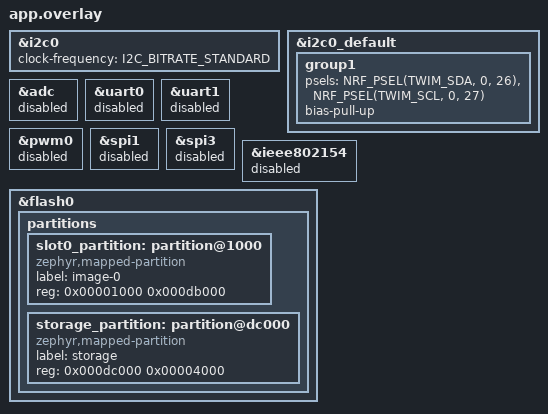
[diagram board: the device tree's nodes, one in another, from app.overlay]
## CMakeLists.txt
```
cmake_minimum_required(VERSION 3.20.0)
find_package(Zephyr REQUIRED HINTS $ENV{ZEPHYR_BASE})
project(nu40_imu_bringup)
target_include_directories(app PRIVATE include)
target_sources(app PRIVATE src/main.c src/imu_device.c src/imu_calibration.c src/imu_storage.c)
```

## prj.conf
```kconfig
CONFIG_GPIO=y
CONFIG_I2C=y
CONFIG_PINCTRL=y
CONFIG_CONSOLE=y
CONFIG_PRINTK=y
CONFIG_SHELL=y
CONFIG_SHELL_BACKEND_SERIAL=y
CONFIG_SHELL_VT100_COLORS=n
CONFIG_SHELL_STACK_SIZE=4096
CONFIG_UART_LINE_CTRL=y
CONFIG_LOG=y
CONFIG_LOG_MODE_DEFERRED=y
CONFIG_LOG_PROCESS_TRIGGER_THRESHOLD=1
CONFIG_LOG_PROCESS_THREAD_SLEEP_MS=20
CONFIG_LOG_DEFAULT_LEVEL=3
CONFIG_LOG_BACKEND_UART=n
CONFIG_LOG_BACKEND_SHOW_COLOR=n
CONFIG_LOG_BUFFER_SIZE=8192
CONFIG_CBPRINTF_FP_SUPPORT=y
CONFIG_MAIN_STACK_SIZE=4096
CONFIG_SYSTEM_WORKQUEUE_STACK_SIZE=2048
CONFIG_ASSERT=y
CONFIG_FLASH=y
CONFIG_FLASH_PAGE_LAYOUT=y
CONFIG_FLASH_MAP=y
CONFIG_NVS=y
CONFIG_NVS_DATA_CRC=y
CONFIG_BUILD_OUTPUT_UF2=y
CONFIG_USE_DT_CODE_PARTITION=y
```

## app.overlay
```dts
/* BARAM-NU40 UF2 bootloader, no SoftDevice: direct application starts at 0x1000.
 * Verified from this board's INFO_UF2.TXT. Not for the older NRF52BOOT/S140 board.
 */
&i2c0 {
	status = "okay";
	clock-frequency = <I2C_BITRATE_STANDARD>;
};

&i2c0_default {
	group1 {
		psels = <NRF_PSEL(TWIM_SDA, 0, 26)>, <NRF_PSEL(TWIM_SCL, 0, 27)>;
		bias-pull-up;
	};
};

&adc { status = "disabled"; };
&uart0 { status = "disabled"; };
&uart1 { status = "disabled"; };
&pwm0 { status = "disabled"; };
&spi1 { status = "disabled"; };
&spi3 { status = "disabled"; };
&ieee802154 { status = "disabled"; };

&flash0 {
	partitions {
		/delete-node/ partition@1000;
		/delete-node/ partition@10000;
		/delete-node/ partition@76000;
		/delete-node/ partition@dc000;

		slot0_partition: partition@1000 {
			compatible = "zephyr,mapped-partition";
			label = "image-0";
			reg = <0x00001000 0x000db000>;
		};
		storage_partition: partition@dc000 {
			compatible = "zephyr,mapped-partition";
			label = "storage";
			reg = <0x000dc000 0x00004000>;
		};
	};
};
```

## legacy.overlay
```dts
/* Apply after app.overlay for NRF52BOOT with S140 6.1.1.
 * Preserve MBR/SoftDevice below 0x26000 and NVS at 0xdc000..0xe0000.
 */
/* Legacy board revisions may lack a working 32.768 kHz crystal. */
&lfclk {
	k32src = "rc";
	k32src-accuracy-ppm = <500>;
};

&flash0 {
	partitions {
		/delete-node/ partition@1000;
		slot0_partition: partition@26000 {
			compatible = "zephyr,mapped-partition";
			label = "image-0";
			reg = <0x00026000 0x000b6000>;
		};
	};
};
```

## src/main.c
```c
/* SPDX-License-Identifier: Apache-2.0 */
#include "imu_device.h"
#include "imu_calibration.h"
#include "imu_storage.h"

#include <errno.h>
#include <string.h>
#include <zephyr/device.h>
#include <zephyr/drivers/gpio.h>
#include <zephyr/drivers/i2c.h>
#include <zephyr/kernel.h>
#include <zephyr/logging/log.h>
#include <zephyr/shell/shell.h>
#include <zephyr/sys/atomic.h>

LOG_MODULE_REGISTER(nu40_imu, LOG_LEVEL_INF);

static const struct device *const bus = DEVICE_DT_GET(DT_NODELABEL(i2c0));
static const struct device *const gpio0 = DEVICE_DT_GET(DT_NODELABEL(gpio0));
static K_MUTEX_DEFINE(state_lock);
static struct imu_device imu;
static struct imu_calibration cal;
static uint8_t address;
static double bias[3];
static bool bias_valid, calibrating, storage_attempted;
static bool connected_before;
static uint8_t previous_address, previous_who;
static uint32_t fresh, stale, errors, late, reconnects, consecutive_errors;
static int last_error, storage_error = -ENODEV;
static int64_t last_fresh, cal_started;
static atomic_t streaming = ATOMIC_INIT(1);
static atomic_t pending;
enum { REQ_NONE, REQ_RETRY, REQ_CALIBRATE, REQ_SAVE, REQ_CLEAR };

static int read_bus_levels(gpio_port_value_t *levels)
{
	/* Read the input register only; never change pins owned by the I2C driver. */
	return device_is_ready(gpio0) ? gpio_port_get_raw(gpio0, levels) : -ENODEV;
}

static int bus_read(void *ctx, uint8_t reg, uint8_t *data, size_t size)
{
	return i2c_write_read(bus, *(uint8_t *)ctx, &reg, 1, data, size);
}

static int bus_write(void *ctx, uint8_t reg, uint8_t value)
{
	return i2c_reg_write_byte(bus, *(uint8_t *)ctx, reg, value);
}

static void bus_sleep(void *ctx, unsigned ms)
{
	ARG_UNUSED(ctx);
	k_msleep(ms);
}

static int command_request(const struct shell *sh, int request)
{
	if (!atomic_cas(&pending, REQ_NONE, request)) {
		shell_error(sh, "A command is already pending");
		return -EBUSY;
	}
	shell_print(sh, "Request queued");
	return 0;
}

#define REQUEST_COMMAND(name, value) \
	static int name(const struct shell *sh, size_t argc, char **argv) \
	{ ARG_UNUSED(argc); ARG_UNUSED(argv); return command_request(sh, value); }
REQUEST_COMMAND(cmd_retry, REQ_RETRY)
REQUEST_COMMAND(cmd_calibrate, REQ_CALIBRATE)
REQUEST_COMMAND(cmd_save, REQ_SAVE)
REQUEST_COMMAND(cmd_clear, REQ_CLEAR)

static int cmd_status(const struct shell *sh, size_t argc, char **argv)
{
	ARG_UNUSED(argc); ARG_UNUSED(argv);
	k_mutex_lock(&state_lock, K_FOREVER);
	shell_print(sh, "NU40-DK IMU v1.1: SDA=P0.26 SCL=P0.27 I2C=100000 Hz");
	gpio_port_value_t levels;
	if (read_bus_levels(&levels) == 0) {
		shell_print(sh, "bus_levels: SDA=%d SCL=%d (idle should be 1/1)",
			!!(levels & BIT(26)), !!(levels & BIT(27)));
	}
	shell_print(sh, "ready=%d address=0x%02x profile=%s last_error=%d stage=%s",
		imu.ready, address, imu_device_name(&imu), last_error,
		imu.stage ? imu.stage : "waiting");
	if (imu.id_valid) {
		shell_print(sh, "WHO_AM_I=0x%02x", imu.who_am_i);
	} else {
		shell_print(sh, "WHO_AM_I=unavailable (no successful ID read)");
	}
	shell_print(sh, "fresh=%u stale=%u errors=%u late=%u reconnects=%u age_ms=%lld",
		fresh, stale, errors, late, reconnects,
		fresh ? k_uptime_get() - last_fresh : -1LL);
	shell_print(sh, "calibrating=%d count=%u bias_valid=%d bias_dps=%.6f,%.6f,%.6f storage=%d",
		calibrating, cal.count, bias_valid, bias[0], bias[1], bias[2], storage_error);
	k_mutex_unlock(&state_lock);
	return 0;
}

static int cmd_stream(const struct shell *sh, size_t argc, char **argv)
{
	ARG_UNUSED(argc);
	if (!strcmp(argv[1], "on")) {
		atomic_set(&streaming, 1);
	} else if (!strcmp(argv[1], "off")) {
		atomic_set(&streaming, 0);
	} else {
		shell_error(sh, "Usage: imu stream on|off");
		return -EINVAL;
	}
	shell_print(sh, "Sample stream %s", argv[1]);
	return 0;
}

SHELL_STATIC_SUBCMD_SET_CREATE(imu_commands,
	SHELL_CMD_ARG(status, NULL, "Show sensor identity and health", cmd_status, 1, 0),
	SHELL_CMD_ARG(retry, NULL, "Probe 0x6a/0x6b and reinitialize", cmd_retry, 1, 0),
	SHELL_CMD_ARG(stream, NULL, "on|off: sample logging", cmd_stream, 2, 0),
	SHELL_CMD_ARG(calibrate, NULL, "Keep still for 1000 fresh samples", cmd_calibrate, 1, 0),
	SHELL_CMD_ARG(save, NULL, "Save accepted gyro bias", cmd_save, 1, 0),
	SHELL_CMD_ARG(clear, NULL, "Clear saved and RAM bias", cmd_clear, 1, 0),
	SHELL_SUBCMD_SET_END);
SHELL_CMD_REGISTER(imu, &imu_commands, "NU40-DK IMU diagnostics", NULL);

/* Called by the acquisition thread with state_lock held; only it uses I2C. */
static bool connect_sensor(void)
{
	imu.ready = false;
	calibrating = false;
	if (!device_is_ready(bus)) {
		imu.id_valid = false;
		imu.stage = "i2c-controller-not-ready";
		last_error = -ENODEV;
		LOG_ERR("I2C controller not ready; retrying in 2 seconds");
		return false;
	}
	gpio_port_value_t levels;
	if (read_bus_levels(&levels) == 0) {
		LOG_INF("I2C idle before probe: SDA=%d SCL=%d (expected 1/1)",
			!!(levels & BIT(26)), !!(levels & BIT(27)));
	}
	for (uint8_t candidate = 0x6a; candidate <= 0x6b; ++candidate) {
		address = candidate;
		imu.io = (struct imu_io){
			.read = bus_read, .write = bus_write,
			.sleep_ms = bus_sleep, .ctx = &address,
		};
		last_error = imu_device_init(&imu);
		if (imu.id_valid) {
			LOG_INF("probe addr=0x%02x WHO_AM_I=0x%02x profile=%s init=%d stage=%s",
				address, imu.who_am_i, imu_device_name(&imu), last_error, imu.stage);
		} else {
			LOG_WRN("probe addr=0x%02x WHO_AM_I=unavailable read_error=%d stage=%s",
				address, last_error, imu.stage);
		}
		if (last_error == 0) {
			++reconnects;
			consecutive_errors = 0;
			last_fresh = k_uptime_get();
			if (!storage_attempted) {
				storage_error = imu_storage_init();
				storage_attempted = true;
			}
			if (!connected_before || previous_address != address || previous_who != imu.who_am_i) {
				memset(bias, 0, sizeof(bias));
				int loaded = storage_error ? storage_error : imu_storage_load(imu.who_am_i, bias);
				bias_valid = loaded == 0;
				LOG_INF("Calibration load result=%d bias_valid=%d (missing record is normal)", loaded, bias_valid);
			} else {
				LOG_INF("Reconnected same profile/address; current RAM bias retained");
			}
			connected_before = true;
			previous_address = address;
			previous_who = imu.who_am_i;
			LOG_INF("IMU ready: profile=%s addr=0x%02x; sensor=104 Hz poll=100 Hz", imu_device_name(&imu), address);
			return true;
		}
	}
	LOG_WRN("No ready IMU; retrying in 2 seconds. Shell remains available.");
	return false;
}

static void process_request(void)
{
	int request = atomic_set(&pending, REQ_NONE);
	if (request == REQ_NONE) { return; }
	if (request == REQ_RETRY) {
		imu.ready = false;
		calibrating = false;
		return;
	}
	if (!imu.ready) {
		LOG_WRN("Command rejected: IMU not ready; use imu status");
		return;
	}
	if (request == REQ_CALIBRATE) {
		imu_cal_begin(&cal);
		calibrating = true;
		cal_started = k_uptime_get();
		LOG_INF("Calibration started: keep sensor still for ~10 seconds");
	} else if (request == REQ_SAVE) {
		if (!bias_valid || calibrating) {
			LOG_WRN("Save rejected: first complete calibration");
		} else {
			int rc = imu_storage_save(imu.who_am_i, bias);
			LOG_INF("Calibration save result=%d", rc);
		}
	} else if (request == REQ_CLEAR) {
		int rc = imu_storage_clear();
		if (rc == 0 || rc == -ENOENT) {
			memset(bias, 0, sizeof(bias));
			bias_valid = false;
			calibrating = false;
		}
		LOG_INF("Calibration clear result=%d", rc);
	}
}

int main(void)
{
	int64_t next_log = 0, next_health = 0, next_retry = 0;
	uint32_t previous_fresh = 0;

	k_msleep(1000);
	LOG_INF("NU40-DK IMU v1.1 (%s %s)", __DATE__, __TIME__);
	LOG_INF("NU40 app=0x%lx; SDA=P0.26 SCL=P0.27 I2C=100000 Hz; USB CDC",
		(unsigned long)DT_REG_ADDR(DT_CHOSEN(zephyr_code_partition)));
	LOG_INF("Commands: imu status | retry | stream on/off | calibrate | save | clear");
	int64_t next = k_uptime_get();
	next_health = next + 10000;
	while (true) {
		k_mutex_lock(&state_lock, K_FOREVER);
		bool forced_retry = atomic_get(&pending) == REQ_RETRY;
		process_request();
		int64_t now = k_uptime_get();
		if (!imu.ready && (forced_retry || now >= next_retry)) {
			connect_sensor();
			now = k_uptime_get();
			next_retry = now + 2000;
			next = now;
		}
		if (imu.ready) {
			struct imu_sample sample;
			int rc = imu_device_read(&imu, &sample);
			now = k_uptime_get();
			if (calibrating && (now - cal_started > 15000 || now - last_fresh > 100)) {
				calibrating = false;
				LOG_WRN("Calibration cancelled: timeout or missing samples");
			}
			if (rc == 0) {
				++fresh;
				last_fresh = now;
				last_error = 0;
				consecutive_errors = 0;
				if (calibrating) {
					struct imu_measurement measurement;
					memcpy(measurement.accel_g, sample.accel_g, sizeof(sample.accel_g));
					memcpy(measurement.gyro_dps, sample.gyro_dps, sizeof(sample.gyro_dps));
					int result = imu_cal_add(&cal, &measurement);
					if (result != 0) {
						calibrating = false;
						if (result > 0) {
							memcpy(bias, cal.mean + 3, sizeof(bias));
							bias_valid = true;
							LOG_INF("Calibration accepted: count=%u bias_dps=%.6f,%.6f,%.6f; use imu save", cal.count, bias[0], bias[1], bias[2]);
						} else {
							LOG_WRN("Calibration rejected: motion/noise/range count=%u", cal.count);
						}
					}
				}
				if (atomic_get(&streaming) && now >= next_log) {
					LOG_INF("sample=%u accel_g=%.4f,%.4f,%.4f gyro_dps=%.4f,%.4f,%.4f corrected_dps=%.4f,%.4f,%.4f",
						fresh, sample.accel_g[0], sample.accel_g[1], sample.accel_g[2],
						sample.gyro_dps[0], sample.gyro_dps[1], sample.gyro_dps[2],
						sample.gyro_dps[0] - bias[0], sample.gyro_dps[1] - bias[1], sample.gyro_dps[2] - bias[2]);
					next_log = now + 100;
				}
			} else if (rc == -EAGAIN) {
				++stale;
			} else {
				++errors;
				++consecutive_errors;
				last_error = rc;
				calibrating = false;
				if (consecutive_errors == 1) {
					LOG_ERR("Sample failed rc=%d stage=%s", rc, imu.stage);
				}
			}
			if (consecutive_errors >= 5 || now - last_fresh > 1000) {
				imu.ready = false;
				calibrating = false;
				next_retry = now + 500;
				LOG_WRN("Sensor stalled; scheduling reinitialization");
			}
		}
		if (now >= next_health) {
			LOG_INF("health: ready=%d fresh=%u delta_10s=%u stale=%u errors=%u late=%u",
				imu.ready, fresh, fresh - previous_fresh, stale, errors, late);
			previous_fresh = fresh;
			next_health = now + 10000;
		}
		next += 10;
		if (now > next) { ++late; next = now + 10; }
		k_mutex_unlock(&state_lock);
		k_sleep(K_TIMEOUT_ABS_MS(next));
	}
	return 0;
}
```

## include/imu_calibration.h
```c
/* SPDX-License-Identifier: Apache-2.0 */
#ifndef MW_IMU_CALIBRATION_H
#define MW_IMU_CALIBRATION_H

#include <stdbool.h>
#include <stdint.h>

#define IMU_CAL_SAMPLES 1000U

struct imu_measurement {
	double accel_g[3];
	double gyro_dps[3];
};

struct imu_calibration {
	uint32_t count;
	double mean[6];
	double m2[6];
	bool rejected;
};

void imu_cal_begin(struct imu_calibration *cal);
/* Returns 0 while collecting, 1 when accepted, or a negative errno on rejection. */
int imu_cal_add(struct imu_calibration *cal, const struct imu_measurement *sample);
double imu_cal_stddev(const struct imu_calibration *cal, unsigned int channel);
bool imu_bias_valid(const double bias[3]);

#endif
```

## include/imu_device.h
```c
#ifndef NU40_IMU_DEVICE_H
#define NU40_IMU_DEVICE_H

#include <stdbool.h>
#include <stddef.h>
#include <stdint.h>

/* The transport owns the I2C address. Return 0 on success or negative errno. */
struct imu_io {
	int (*read)(void *ctx, uint8_t reg, uint8_t *data, size_t len);
	int (*write)(void *ctx, uint8_t reg, uint8_t value);
	void (*sleep_ms)(void *ctx, unsigned ms);
	void *ctx;
};

struct imu_device {
	struct imu_io io;
	uint8_t who_am_i;
	/* false means that who_am_i must NOT be reported as a sensor response. */
	bool id_valid;
	bool ready;
	const char *stage;
};

struct imu_sample {
	double accel_g[3];
	double gyro_dps[3];
};

/* Preserves io and resets all diagnostic state, including stale identity. */
int imu_device_init(struct imu_device *dev);

/* Requires new gyro AND accelerometer data; leaves sample unchanged on error.
 * -EAGAIN is normal while waiting for a fresh sample. Axes are sensor-native.
 */
int imu_device_read(struct imu_device *dev, struct imu_sample *sample);

/* Diagnostic name for the supported register profile selected by WHO_AM_I. */
const char *imu_device_name(const struct imu_device *dev);

#endif
```

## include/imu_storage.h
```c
/* SPDX-License-Identifier: Apache-2.0 */
#ifndef MW_IMU_STORAGE_H
#define MW_IMU_STORAGE_H
#include <stdint.h>
int imu_storage_init(void);
int imu_storage_load(uint8_t who, double bias[3]);
int imu_storage_save(uint8_t who, const double bias[3]);
int imu_storage_clear(void);
#endif
```

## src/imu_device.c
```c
#include "imu_device.h"

#include <errno.h>

/* Register layout and sensitivities checked against the ST platform drivers:
 * https://github.com/STMicroelectronics/lsm6ds3-pid
 * https://github.com/STMicroelectronics/lsm6ds3tr-c-pid
 * Only their common basic accel/gyro register subset is used here.
 */
enum {
	REG_WHO_AM_I = 0x0f,
	REG_CTRL1_XL = 0x10,
	REG_CTRL2_G = 0x11,
	REG_CTRL3_C = 0x12,
	REG_STATUS = 0x1e,
	REG_OUTX_L_G = 0x22,
	WHO_LSM6DS3 = 0x69,
	WHO_LSM6DS3TR_C = 0x6a,
	CTRL3_SW_RESET = 0x01,
	CTRL3_BDU_IF_INC = 0x44,
	CTRL1_104HZ_2G = 0x40,
	CTRL2_104HZ_FS0 = 0x40,
	STATUS_ACCEL_GYRO_READY = 0x03,
	RESET_POLL_COUNT = 50,
	RESET_POLL_MS = 2,
};

static int checked_write(struct imu_device *dev, uint8_t reg, uint8_t value,
			 const char *write_stage, const char *read_stage,
			 const char *mismatch_stage)
{
	uint8_t actual;
	int err;

	dev->stage = write_stage;
	err = dev->io.write(dev->io.ctx, reg, value);
	if (err != 0) {
		return err;
	}
	dev->stage = read_stage;
	err = dev->io.read(dev->io.ctx, reg, &actual, 1);
	if (err != 0) {
		return err;
	}
	if (actual != value) {
		dev->stage = mismatch_stage;
		return -EIO;
	}
	return 0;
}

const char *imu_device_name(const struct imu_device *dev)
{
	if (dev == NULL || !dev->id_valid) {
		return "unidentified";
	}
	switch (dev->who_am_i) {
	case WHO_LSM6DS3:
		return "LSM6DS3";
	case WHO_LSM6DS3TR_C:
		return "LSM6DS3TR-C";
	default:
		return "unsupported";
	}
}

int imu_device_init(struct imu_device *dev)
{
	uint8_t who;
	uint8_t ctrl3 = CTRL3_SW_RESET;
	int err;

	if (dev == NULL) {
		return -EINVAL;
	}
	dev->who_am_i = 0;
	dev->id_valid = false;
	dev->ready = false;
	dev->stage = "validate-transport";
	if (dev->io.read == NULL || dev->io.write == NULL ||
	    dev->io.sleep_ms == NULL) {
		return -EINVAL;
	}

	dev->stage = "power-on-settle";
	dev->io.sleep_ms(dev->io.ctx, 100);
	dev->stage = "read-WHO_AM_I";
	err = dev->io.read(dev->io.ctx, REG_WHO_AM_I, &who, 1);
	if (err != 0) {
		return err;
	}
	dev->who_am_i = who;
	dev->id_valid = true;
	dev->stage = "unsupported-WHO_AM_I";
	if (who != WHO_LSM6DS3 && who != WHO_LSM6DS3TR_C) {
		return -ENODEV;
	}

	/* An acknowledged but unknown device must never receive reset/config writes. */
	dev->stage = "write-reset";
	err = dev->io.write(dev->io.ctx, REG_CTRL3_C, CTRL3_SW_RESET);
	if (err != 0) {
		return err;
	}
	dev->stage = "read-reset-status";
	for (unsigned poll = 0; poll < RESET_POLL_COUNT; ++poll) {
		dev->io.sleep_ms(dev->io.ctx, RESET_POLL_MS);
		err = dev->io.read(dev->io.ctx, REG_CTRL3_C, &ctrl3, 1);
		if (err != 0) {
			return err;
		}
		if ((ctrl3 & CTRL3_SW_RESET) == 0) {
			break;
		}
	}
	if ((ctrl3 & CTRL3_SW_RESET) != 0) {
		dev->stage = "reset-timeout";
		return -ETIMEDOUT;
	}

	err = checked_write(dev, REG_CTRL3_C, CTRL3_BDU_IF_INC,
			    "write-CTRL3_C", "read-CTRL3_C", "verify-CTRL3_C");
	if (err != 0) {
		return err;
	}
	err = checked_write(dev, REG_CTRL1_XL, CTRL1_104HZ_2G,
			    "write-CTRL1_XL", "read-CTRL1_XL", "verify-CTRL1_XL");
	if (err != 0) {
		return err;
	}
	err = checked_write(dev, REG_CTRL2_G, CTRL2_104HZ_FS0,
			    "write-CTRL2_G", "read-CTRL2_G", "verify-CTRL2_G");
	if (err != 0) {
		return err;
	}

	dev->stage = "sensor-settle";
	dev->io.sleep_ms(dev->io.ctx, 100);
	dev->ready = true;
	dev->stage = "ready";
	return 0;
}

static int32_t signed_le16(const uint8_t *bytes)
{
	uint32_t word = (uint32_t)bytes[0] | ((uint32_t)bytes[1] << 8);

	/* Avoid implementation-defined uint16_t -> int16_t conversion. */
	return word >= 0x8000U ? (int32_t)word - 65536 : (int32_t)word;
}

int imu_device_read(struct imu_device *dev, struct imu_sample *sample)
{
	uint8_t status;
	uint8_t raw[12];
	struct imu_sample next;
	int err;

	if (dev == NULL || sample == NULL) {
		return -EINVAL;
	}
	if (!dev->ready) {
		return -ENODEV;
	}
	dev->stage = "read-STATUS_REG";
	err = dev->io.read(dev->io.ctx, REG_STATUS, &status, 1);
	if (err != 0) {
		return err;
	}
	if ((status & STATUS_ACCEL_GYRO_READY) != STATUS_ACCEL_GYRO_READY) {
		dev->stage = "wait-fresh-sample";
		return -EAGAIN;
	}
	dev->stage = "read-gyro-accel-burst";
	err = dev->io.read(dev->io.ctx, REG_OUTX_L_G, raw, sizeof(raw));
	if (err != 0) {
		return err;
	}
	for (unsigned axis = 0; axis < 3; ++axis) {
		next.gyro_dps[axis] = signed_le16(&raw[axis * 2]) * 0.00875;
		next.accel_g[axis] = signed_le16(&raw[6 + axis * 2]) * 0.000061;
	}
	*sample = next;
	dev->stage = "sample-ready";
	return 0;
}
```

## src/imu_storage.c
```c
/* SPDX-License-Identifier: Apache-2.0 */
#include "imu_calibration.h"
#include "imu_storage.h"

#include <errno.h>
#include <math.h>
#include <zephyr/drivers/flash.h>
#include <zephyr/kvss/nvs.h>
#include <zephyr/storage/flash_map.h>
#include <zephyr/sys/byteorder.h>

#define CAL_KEY 0x1701
#define CAL_SIZE 24
#define CAL_MAGIC 0x4d574943U

static struct nvs_fs fs;
static bool mounted;

int imu_storage_init(void)
{
	const struct flash_area *area;
	struct flash_pages_info page;
	int rc = flash_area_open(PARTITION_ID(storage_partition), &area);

	if (rc != 0) {
		return rc;
	}
	fs.flash_device = area->fa_dev;
	fs.offset = area->fa_off;
	rc = flash_get_page_info_by_offs(fs.flash_device, fs.offset, &page);
	if (rc == 0 && (page.size == 0 || page.size > UINT16_MAX ||
	    area->fa_off % page.size || area->fa_size % page.size ||
	    area->fa_size / page.size < 2)) {
		rc = -EINVAL;
	}
	if (rc == 0) {
		fs.sector_size = page.size;
		fs.sector_count = area->fa_size / page.size;
		rc = nvs_mount(&fs);
	}
	flash_area_close(area);
	mounted = rc == 0;
	/* Never erase the partition as an automatic mount-error recovery. */
	return rc;
}

int imu_storage_load(uint8_t who, double bias[3])
{
	uint8_t record[CAL_SIZE];
	double next[3];
	ssize_t rc;

	if (!mounted) {
		return -ENODEV;
	}
	rc = nvs_read(&fs, CAL_KEY, record, sizeof(record));
	if (rc < 0) {
		return rc;
	}
	if (rc != sizeof(record) || sys_get_le32(record) != CAL_MAGIC ||
	    sys_get_le32(record + 4) != 1 || sys_get_le32(record + 8) != who) {
		return -EBADMSG;
	}
	for (int i = 0; i < 3; ++i) {
		uint32_t bits = sys_get_le32(record + 12 + i * 4);
		int64_t value = bits <= INT32_MAX ? (int64_t)bits : (int64_t)bits - 4294967296LL;
		next[i] = value / 1000000.0;
	}
	if (!imu_bias_valid(next)) {
		return -ERANGE;
	}
	for (int i = 0; i < 3; ++i) {
		bias[i] = next[i];
	}
	return 0;
}

int imu_storage_save(uint8_t who, const double bias[3])
{
	uint8_t record[CAL_SIZE];
	ssize_t rc;

	if (!mounted) {
		return -ENODEV;
	}
	if (!imu_bias_valid(bias)) {
		return -ERANGE;
	}
	sys_put_le32(CAL_MAGIC, record);
	sys_put_le32(1, record + 4);
	sys_put_le32(who, record + 8);
	for (int i = 0; i < 3; ++i) {
		sys_put_le32((uint32_t)(int32_t)lround(bias[i] * 1000000), record + 12 + i * 4);
	}
	rc = nvs_write(&fs, CAL_KEY, record, sizeof(record));
	/* nvs_write returns zero when the exact record is already stored. */
	return rc == 0 || rc == sizeof(record) ? 0 : (rc < 0 ? (int)rc : -EIO);
}

int imu_storage_clear(void)
{
	return mounted ? nvs_delete(&fs, CAL_KEY) : -ENODEV;
}
```
